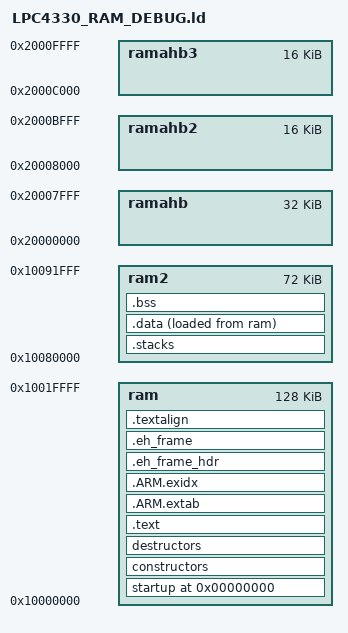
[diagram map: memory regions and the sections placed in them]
/*
    ChibiOS/RT - Copyright (C) 2006,2007,2008,2009,2010,
                 2011,2012,2013 Giovanni Di Sirio.

    This file is part of ChibiOS/RT.

    ChibiOS/RT is free software; you can redistribute it and/or modify
    it under the terms of the GNU General Public License as published by
    the Free Software Foundation; either version 3 of the License, or
    (at your option) any later version.

    ChibiOS/RT is distributed in the hope that it will be useful,
    but WITHOUT ANY WARRANTY; without even the implied warranty of
    MERCHANTABILITY or FITNESS FOR A PARTICULAR PURPOSE.  See the
    GNU General Public License for more details.

    You should have received a copy of the GNU General Public License
    along with this program.  If not, see <http://www.gnu.org/licenses/>.
*/

/*
 * LPC4330 ROMless memory setup.
 * Code runs from ram.
 */
__main_stack_size__     = 0x0800;
__process_stack_size__  = 0x0800;

MEMORY
{
    ram     : org = 0x10000000, len = 128k
    ram2    : org = 0x10080000, len = 72k
    ramahb  : org = 0x20000000, len = 32k
    ramahb2 : org = 0x20008000, len = 16k
    ramahb3 : org = 0x2000C000, len = 16k
}

__ram_start__           = ORIGIN(ram2);
__ram_size__            = LENGTH(ram2);
__ram_end__             = __ram_start__ + __ram_size__;

ENTRY(ResetHandler)

SECTIONS
{
    . = 0;
    _text = .;

    startup : ALIGN(16) SUBALIGN(16)
    {
    	__vectors_start = .;
        KEEP(*(vectors))
    } > ram

    constructors : ALIGN(4) SUBALIGN(4)
    {
        PROVIDE(__init_array_start = .);
        KEEP(*(SORT(.init_array.*)))
        KEEP(*(.init_array))
        PROVIDE(__init_array_end = .);
    } > ram

    destructors : ALIGN(4) SUBALIGN(4)
    {
        PROVIDE(__fini_array_start = .);
        KEEP(*(.fini_array))
        KEEP(*(SORT(.fini_array.*)))
        PROVIDE(__fini_array_end = .);
    } > ram

    .text : ALIGN(16) SUBALIGN(16)
    {
        *(.text.startup.*)
        *(.text)
        *(.text.*)
        *(.rodata)
        *(.rodata.*)
        *(.glue_7t)
        *(.glue_7)
        *(.gcc*)
    } > ram

    .ARM.extab :
    {
        *(.ARM.extab* .gnu.linkonce.armextab.*)
    } > ram

    .ARM.exidx : {
        PROVIDE(__exidx_start = .);
        *(.ARM.exidx* .gnu.linkonce.armexidx.*)
        PROVIDE(__exidx_end = .);
     } > ram

    .eh_frame_hdr :
    {
        *(.eh_frame_hdr)
    } > ram

    .eh_frame : ONLY_IF_RO
    {
        *(.eh_frame)
    } > ram
    
    .textalign : ONLY_IF_RO
    {
        . = ALIGN(8);
    } > ram

    _etext = .;
    _textdata = _etext;

    .stacks :
    {
        . = ALIGN(8);
        __main_stack_base__ = .;
        . += __main_stack_size__;
        . = ALIGN(8);
        __main_stack_end__ = .;
        __process_stack_base__ = .;
        __main_thread_stack_base__ = .;
        . += __process_stack_size__;
        . = ALIGN(8);
        __process_stack_end__ = .;
        __main_thread_stack_end__ = .;
    } > ram2

    .data :
    {
        . = ALIGN(4);
        PROVIDE(_data = .);
        *(.data)
        . = ALIGN(4);
        *(.data.*)
        . = ALIGN(4);
        *(.ramtext)
        . = ALIGN(4);
        PROVIDE(_edata = .);
    } > ram2 AT > ram

    .bss :
    {
        . = ALIGN(4);
        PROVIDE(_bss_start = .);
        *(.bss)
        . = ALIGN(4);
        *(.bss.*)
        . = ALIGN(4);
        *(COMMON)
        . = ALIGN(4);
        PROVIDE(_bss_end = .);
    } > ram2    
}

PROVIDE(end = .);
_end            = .;

__heap_base__   = _end;
__heap_end__    = __ram_end__;
